# STM32F7x register map
File version: 1.1 AdaCore modified
Registers are 32-bit, read-write, reset 0x0 unless marked. A register's access mark holds for its fields unless they carry their own. Offsets are from the block's base; [hi:lo] are bit positions; {n}, {i} and the like mark numbered series.

## Ethernet_PTP — Ethernet: Precision time protocol
Base 0x40028700
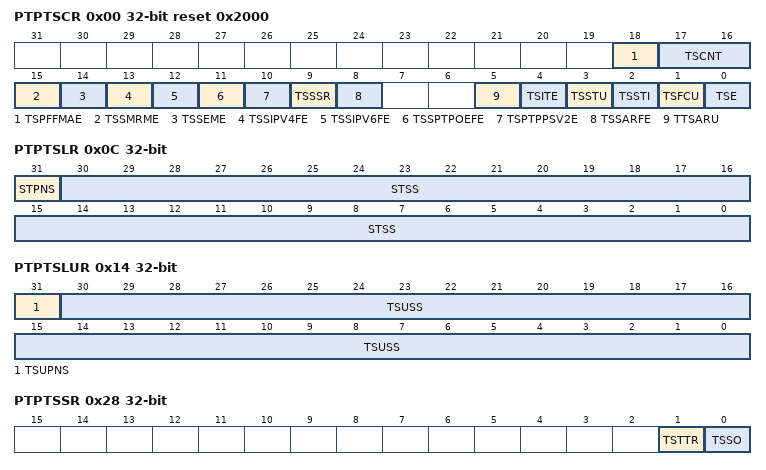
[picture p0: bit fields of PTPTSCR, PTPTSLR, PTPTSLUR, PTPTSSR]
0x00 PTPTSCR reset 0x2000 — Ethernet PTP time stamp control register
  [18] TSPFFMAE, [17:16] TSCNT, [15] TSSMRME, [14] TSSEME, [13] TSSIPV4FE, [12] TSSIPV6FE, [11] TSSPTPOEFE, [10] TSPTPPSV2E, [9] TSSSR, [8] TSSARFE, [5] TTSARU, [4] TSITE, [3] TSSTU, [2] TSSTI, [1] TSFCU, [0] TSE
0x04 PTPSSIR — Ethernet PTP subsecond increment register
  [7:0] STSSI
0x08 PTPTSHR ro — Ethernet PTP time stamp high register
  [31:0] STS
0x0C PTPTSLR ro — Ethernet PTP time stamp low register
  [31] STPNS, [30:0] STSS
0x10 PTPTSHUR — Ethernet PTP time stamp high update register
  [31:0] TSUS
0x14 PTPTSLUR — Ethernet PTP time stamp low update register
  [31] TSUPNS, [30:0] TSUSS
0x18 PTPTSAR — Ethernet PTP time stamp addend register
  [31:0] TSA
0x1C PTPTTHR — Ethernet PTP target time high register
  [31:0] TTSH — 0
0x20 PTPTTLR — Ethernet PTP target time low register
  [31:0] TTSL
0x28 PTPTSSR ro — Ethernet PTP time stamp status register
  [1] TSTTR, [0] TSSO
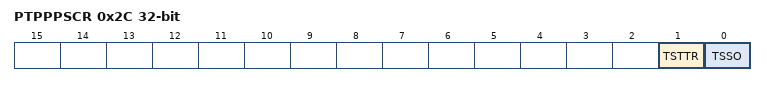
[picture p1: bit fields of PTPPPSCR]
0x2C PTPPPSCR ro — Ethernet PTP PPS control register
  [1] TSTTR, [0] TSSO

## Ethernet_DMA — Ethernet: DMA controller operation
Base 0x40029000
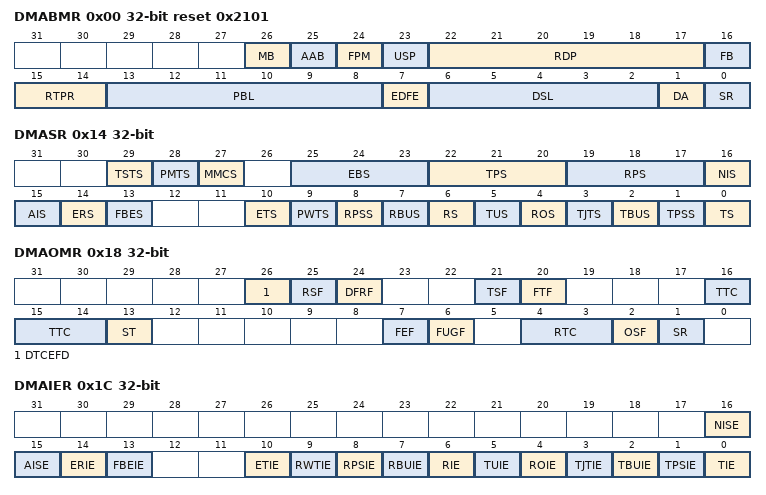
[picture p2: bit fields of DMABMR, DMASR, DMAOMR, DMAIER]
0x00 DMABMR reset 0x2101 — Ethernet DMA bus mode register
  [26] MB, [25] AAB, [24] FPM, [23] USP, [22:17] RDP, [16] FB, [15:14] RTPR, [13:8] PBL, [7] EDFE, [6:2] DSL, [1] DA, [0] SR
0x04 DMATPDR — Ethernet DMA transmit poll demand register
  [31:0] TPD
0x08 DMARPDR — EHERNET DMA receive poll demand register
  [31:0] RPD
0x0C DMARDLAR — Ethernet DMA receive descriptor list address register
  [31:0] SRL
0x10 DMATDLAR — Ethernet DMA transmit descriptor list address register
  [31:0] STL
0x14 DMASR access per field — Ethernet DMA status register
  [29] TSTS ro, [28] PMTS ro, [27] MMCS ro, [25:23] EBS ro, [22:20] TPS ro, [19:17] RPS ro, [16] NIS rw, [15] AIS rw, [14] ERS rw, [13] FBES rw, [10] ETS rw, [9] PWTS rw, [8] RPSS rw, [7] RBUS rw, [6] RS rw, [5] TUS rw, [4] ROS rw, [3] TJTS rw, [2] TBUS rw, [1] TPSS rw, [0] TS rw
0x18 DMAOMR — Ethernet DMA operation mode register
  [26] DTCEFD, [25] RSF, [24] DFRF, [21] TSF, [20] FTF, [16:14] TTC, [13] ST, [7] FEF, [6] FUGF, [4:3] RTC, [2] OSF, [1] SR
0x1C DMAIER — Ethernet DMA interrupt enable register
  [16] NISE, [15] AISE, [14] ERIE, [13] FBEIE, [10] ETIE, [9] RWTIE, [8] RPSIE, [7] RBUIE, [6] RIE, [5] TUIE, [4] ROIE, [3] TJTIE, [2] TBUIE, [1] TPSIE, [0] TIE
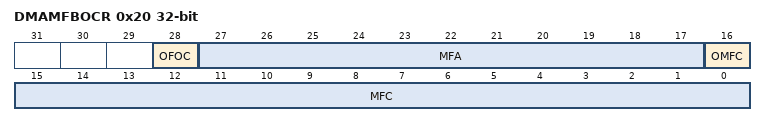
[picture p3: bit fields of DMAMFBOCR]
0x20 DMAMFBOCR — Ethernet DMA missed frame and buffer overflow counter register
  [28] OFOC, [27:17] MFA, [16] OMFC, [15:0] MFC
0x24 DMARSWTR — Ethernet DMA receive status watchdog timer register
  [7:0] RSWTC
0x48 DMACHTDR ro — Ethernet DMA current host transmit descriptor register
  [31:0] HTDAP
0x4C DMACHRDR ro — Ethernet DMA current host receive descriptor register
  [31:0] HRDAP
0x50 DMACHTBAR ro — Ethernet DMA current host transmit buffer address register
  [31:0] HTBAP
0x54 DMACHRBAR ro — Ethernet DMA current host receive buffer address register
  [31:0] HRBAP

## CRC — Cryptographic processor
Base 0x40023000
0x00 DR reset 0xFFFFFFFF — Data register
  [31:0] DR — Data Register
0x04 IDR — Independent Data register
  [7:0] IDR
0x08 CR wo — Control register
  [0] CR — Control regidter
0x0C INIT — Initial CRC value
  [31:0] CRC_INIT — Programmable initial CRC value
0x10 POL — CRC polynomial
  [31:0] POL — Programmable polynomial

## NVIC — Nested Vectored Interrupt Controller
Base 0xE000E000
0x04 ICTR ro — Interrupt Controller Type Register
  [3:0] INTLINESNUM — Total number of interrupt lines in groups
{0x100+4i} ISER{i} (i=0..2) — Interrupt Set-Enable Register
  [31:0] SETENA
{0x180+4i} ICER{i} (i=0..2) — Interrupt Clear-Enable Register
  [31:0] CLRENA
{0x200+4i} ISPR{i} (i=0..2) — Interrupt Set-Pending Register
  [31:0] SETPEND
{0x280+4i} ICPR{i} (i=0..2) — Interrupt Clear-Pending Register
  [31:0] CLRPEND
{0x300+4i} IABR{i} ro (i=0..2) — Interrupt Active Bit Register
  [31:0] ACTIVE
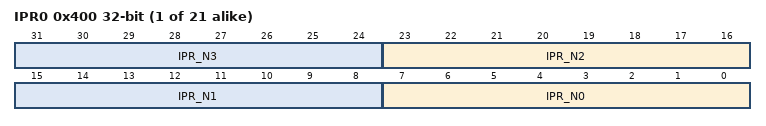
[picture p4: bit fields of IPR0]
{0x400+4i} IPR{i} (i=0..20) — Interrupt Priority Register
  [8n+7:8n] IPR_N{n} (n=0..3)
0xF00 STIR wo — Software Triggered Interrupt Register
  [8:0] INTID — interrupt to be triggered
